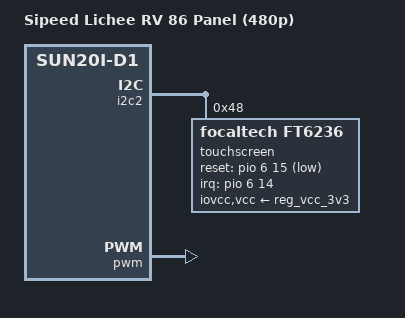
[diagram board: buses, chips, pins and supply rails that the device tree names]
// SPDX-License-Identifier: (GPL-2.0+ OR MIT)
// Copyright (C) 2022 Samuel Holland <samuel@sholland.org>

#include "sun20i-d1-lichee-rv-86-panel.dtsi"

/ {
	model = "Sipeed Lichee RV 86 Panel (480p)";
	compatible = "sipeed,lichee-rv-86-panel-480p", "sipeed,lichee-rv",
		     "allwinner,sun20i-d1";

/*
	backlight: backlight {
		compatible = "pwm-backlight";
		power-supply = <&reg_vcc>;
		pwms = <&pwm 7 50000 0>;
	};

	spi {
		compatible = "spi-gpio";
		cs-gpios = <&pio 4 14 GPIO_ACTIVE_LOW>; // PE14 //
		mosi-gpios = <&pio 4 12 GPIO_ACTIVE_HIGH>; // PE12 //
		sck-gpios = <&pio 4 15 GPIO_ACTIVE_HIGH>; // PE15 //
		num-chipselects = <1>;
		#address-cells = <1>;
		#size-cells = <0>;

		panel@0 {
			compatible = "sitronix,st7701s";
			reg = <0>;
			backlight = <&backlight>;
			reset-gpios = <&pio 6 13 GPIO_ACTIVE_LOW>; // PG13 //
			spi-3wire;

			port {
				panel_in_tcon_lcd0: endpoint {
					remote-endpoint = <&tcon_lcd0_out_panel>;
				};
			};
		};
	};
*/
};

&disp {
	disp_init_enable         = <1>;
	disp_mode                = <0>;

	screen0_output_type      = <1>;
	screen0_output_mode      = <4>;

	screen1_output_type      = <3>;
	screen1_output_mode      = <10>;

	screen1_output_format    = <0>;
	screen1_output_bits      = <0>;
	screen1_output_eotf      = <4>;
	screen1_output_cs        = <257>;
	screen1_output_dvi_hdmi  = <2>;
	screen1_output_range     = <2>;
	screen1_output_scan      = <0>;
	screen1_output_aspect_ratio = <8>;

	dev0_output_type         = <1>;
	dev0_output_mode         = <4>;
	dev0_screen_id           = <0>;
	dev0_do_hpd              = <0>;

	dev1_output_type         = <4>;
	dev1_output_mode         = <10>;
	dev1_screen_id           = <1>;
	dev1_do_hpd              = <1>;

	def_output_dev           = <0>;
	hdmi_mode_check          = <1>;

	fb0_format               = <0>;
	fb0_width                = <0>;
	fb0_height               = <0>;

	fb1_format               = <0>;
	fb1_width                = <0>;
	fb1_height               = <0>;
	chn_cfg_mode             = <1>;

	disp_para_zone           = <1>;
	/*VCC-LCD*/
/*	dc1sw-supply = <&reg_dc1sw>;*/
	/*VCC-DSI*/
/*	eldo3-supply = <&reg_eldo3>;*/
	/*VCC-PD*/
/*	dcdc1-supply = <&reg_dcdc1>;*/

	pwms = <&pwm 7 50000 0>;
};

/*----------------------------------------------------------------------------------
;lcd0 configuration

;lcd_if:               0:hv(sync+de); 1:8080; 2:ttl; 3:lvds; 4:dsi; 5:edp; 6:extend dsi
;lcd_hv_if             0:Parallel RGB; 8:Serial RGB; 10:Dummy RGB; 11: RGB Dummy;12:CCIR656
;lcd_hv_clk_phase      0:0 degree;1:90 degree;2:180 degree;3:270 degree
;lcd_hv_sync_polarity  0:vs low,hs low; 1:vs high,hslow; 2:vs low,hs high; 3:vs high,hs high
;lcd_hv_syuv_seq       0:YUYV; 1:YVYU; 2:UYVY; 3:VYUY
;lcd_cpu_if            0:18bit/1 cycle parallel(RGB666); 4:16bit/1cycle parallel (RGB565)
;                      6:18bit/3 cycle parallel(RGB666); 7:16bit/2cycle parallel (RGB565)
;lcd_cpu_te            0:frame auto trigger; 1:frame triggered by te rising edge; 2:frame triggered by te falling edge;
;lcd_dsi_if            0:video mode; 1: Command mode; 2:video burst mode
;lcd_dsi_te            0:frame auto trigger; 1:frame triggered by te rising edge; 2:frame triggered by te falling edge;
;lcd_x:                lcd horizontal resolution
;lcd_y:                lcd vertical resolution
;lcd_width:            width of lcd in mm
;lcd_height:           height of lcd in mm
;lcd_dclk_freq:        in MHZ unit
;lcd_pwm_freq:         in HZ unit
;lcd_pwm_pol:          lcd backlight PWM polarity
;lcd_pwm_max_limit     lcd backlight PWM max limit(<=255)
;lcd_hbp:              hsync back porch(pixel) + hsync plus width(pixel);
;lcd_ht:               hsync total cycle(pixel)
;lcd_vbp:              vsync back porch(line) + vysnc plus width(line)
;lcd_vt:               vysnc total cycle(line)
;lcd_hspw:             hsync plus width(pixel)
;lcd_vspw:             vysnc plus width(pixel)
;lcd_lvds_if:          0:single link;  1:dual link
;lcd_lvds_colordepth:  0:8bit; 1:6bit
;lcd_lvds_mode:        0:NS mode; 1:JEIDA mode
;lcd_frm:              0:disable; 1:enable rgb666 dither; 2:enable rgb656 dither
;lcd_io_phase:         0:noraml; 1:intert phase(0~3bit: vsync phase; 4~7bit:hsync phase;
;                      8~11bit:dclk phase; 12~15bit:de phase)
;lcd_gamma_en          lcd gamma correction enable
;lcd_bright_curve_en   lcd bright curve correction enable
;lcd_cmap_en           lcd color map function enable
;deu_mode              0:smoll lcd screen; 1:large lcd screen(larger than 10inch)
;lcdgamma4iep:         Smart Backlight parameter, lcd gamma vale * 10;
;                      decrease it while lcd is not bright enough; increase while lcd is too bright
;smart_color           90:normal lcd screen 65:retina lcd screen(9.7inch)
;Pin setting for special function ie.LVDS, RGB data or vsync
;   name(donot care) = port:PD12<pin function><pull up or pull down><drive ability><output level>
;Pin setting for gpio:
;   lcd_gpio_X     = port:PD12<pin function><pull up or pull down><drive ability><output level>
;Pin setting for backlight enable pin
;   lcd_bl_en     = port:PD12<pin function><pull up or pull down><drive ability><output level>
;fsync setting, pulse to csi
;lcd_fsync_en          (0:disable fsync,1:enable)
;lcd_fsync_act_time    (active time of fsync, unit:pixel)
;lcd_fsync_dis_time    (disactive time of fsync, unit:pixel)
;lcd_fsync_pol         (0:positive;1:negative)
;gpio config: <&pio for cpu or &r_pio for cpus, port, port num, pio function,
pull up or pull down(default 0), driver level(default 1), data>
;For dual link lvds: use lvds2link_pins_a  and lvds2link_pins_b instead
;For rgb24: use rgb24_pins_a  and rgb24_pins_b instead
;For lvds1: use lvds1_pins_a  and lvds1_pins_b instead
;For lvds0: use lvds0_pins_a  and lvds0_pins_b instead
;----------------------------------------------------------------------------------*/
&lcd0 {
	lcd_used        = <1>;
	lcd_driver_name = "st7701s_rgb";

	lcd_if          = <0>;
	lcd_hv_if       = <0>;

	lcd_width       = <70>;
	lcd_height      = <72>;
	lcd_x           = <480>;
	lcd_y           = <480>;
	lcd_dclk_freq   = <19>;
	lcd_hbp         = <60>;
	lcd_ht          = <612>;
	lcd_hspw        = <12>;
	lcd_vbp         = <18>;
	lcd_vt          = <520>;
	lcd_vspw        = <4>;

	lcd_backlight   = <50>;
	lcd_pwm_used    = <1>;
	lcd_pwm_ch      = <7>;
	lcd_pwm_freq    = <20000>;
	lcd_pwm_pol     = <1>;
	lcd_bright_curve_en = <0>;

	lcd_frm         = <1>;
	lcd_io_phase    = <0x0000>;
	lcd_gamma_en    = <0>;
	lcd_cmap_en     = <0>;
	lcd_hv_clk_phase= <0>;
	lcd_hv_sync_polarity= <0>;
	lcd_rb_swap          = <0>;

	lcd_power       = "vcc-lcd";
	lcd_pin_power   = "vcc-pd";
	lcd_gpio_0      = <&pio PG 13 GPIO_ACTIVE_HIGH>;
	lcd_gpio_1      = <&pio PE 14 GPIO_ACTIVE_HIGH>;
	lcd_gpio_2      = <&pio PE 12 GPIO_ACTIVE_HIGH>;
	lcd_gpio_3      = <&pio PE 15 GPIO_ACTIVE_HIGH>;
	pinctrl-0       = <&lcd_rgb666_pins>;
	pinctrl-1       = <&lcd_rgb666_sleep_pins>;
};

&hdmi {
	hdmi_used = <1>;
	hdmi_power_cnt = <0>;
	hdmi_cts_compatibility = <1>;
	hdmi_hdcp_enable = <1>;
	hdmi_hdcp22_enable = <0>;
	hdmi_cec_support = <1>;
	hdmi_cec_super_standby = <0>;

	ddc_en_io_ctrl = <0>;
	power_io_ctrl = <0>;
};

/*
&de {
	status = "okay";
};
*/

&i2c2 {
	pinctrl-0 = <&i2c2_pb0_pins>;
	pinctrl-names = "default";
	status = "okay";

	touchscreen@48 {
		compatible = "focaltech,ft6236";
		reg = <0x48>;
		interrupt-parent = <&pio>;
		interrupts = <6 14 IRQ_TYPE_LEVEL_LOW>; /* PG14 */
		iovcc-supply = <&reg_vcc_3v3>;
		reset-gpios = <&pio 6 15 GPIO_ACTIVE_LOW>; /* PG15 */
		touchscreen-size-x = <480>;
		touchscreen-size-y = <480>;
		vcc-supply = <&reg_vcc_3v3>;
		wakeup-source;
	};
};

&pwm {
	pinctrl-0 = <&pwm7_pd22_pin>;
	pinctrl-names = "default";
	status = "okay";
};

/*
&tcon_lcd0 {
	pinctrl-0 = <&lcd_rgb666_pins>;
	pinctrl-names = "default";
};

&tcon_lcd0_out {
	tcon_lcd0_out_panel: endpoint {
		remote-endpoint = <&panel_in_tcon_lcd0>;
	};
};
*/
